# CAN1 register map
Registers from a debugger description file.
Registers are 32-bit, access not given, no defined reset value unless marked. A register's access mark holds for its fields unless they carry their own. Addresses are absolute; registers are grouped by the start of their names; lines under a group give offsets from that group; [hi:lo] are bit positions; {n}, {i} and the like mark numbered series; 'fields as' and 'values as' point back to an identical list; <NAME> marks a mode.

## CAN1
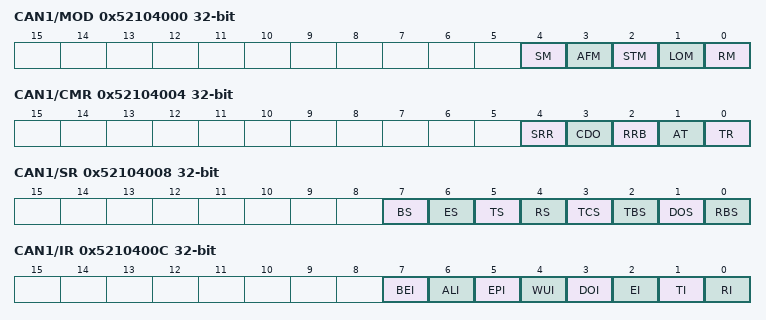
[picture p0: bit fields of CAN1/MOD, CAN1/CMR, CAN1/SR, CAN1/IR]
0x52104000 CAN1/MOD
  [4] SM, [3] AFM, [2] STM, [1] LOM, [0] RM
0x52104004 CAN1/CMR wo
  [4] SRR, [3] CDO, [2] RRB, [1] AT, [0] TR
0x52104008 CAN1/SR ro
  [7] BS, [6] ES, [5] TS, [4] RS, [3] TCS, [2] TBS, [1] DOS, [0] RBS
0x5210400C CAN1/IR ro
  [7] BEI, [6] ALI, [5] EPI, [4] WUI, [3] DOI, [2] EI, [1] TI, [0] RI
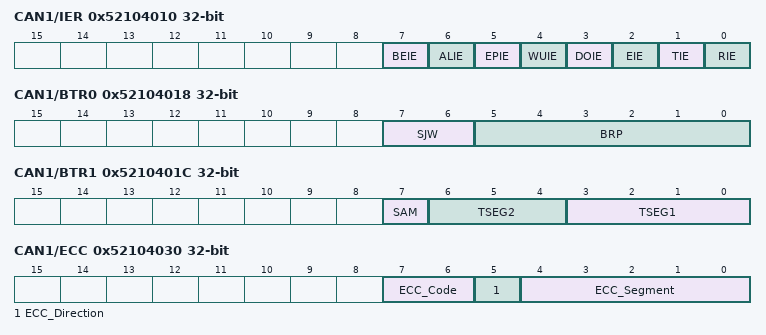
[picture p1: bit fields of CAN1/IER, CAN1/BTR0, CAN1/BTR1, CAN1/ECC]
0x52104010 CAN1/IER
  [7] BEIE, [6] ALIE, [5] EPIE, [4] WUIE, [3] DOIE, [2] EIE, [1] TIE, [0] RIE
0x52104018 CAN1/BTR0
  [7:6] SJW, [5:0] BRP
0x5210401C CAN1/BTR1
  [7] SAM, [6:4] TSEG2, [3:0] TSEG1
0x52104020 CAN1/OCR
  [1:0] OCMODE
0x5210402C CAN1/ALC ro
  [4:0] ALC
0x52104030 CAN1/ECC ro
  [7:6] ECC_Code, [5] ECC_Direction, [4:0] ECC_Segment
0x52104034 CAN1/EWLR
  [7:0] EWLR
0x52104038 CAN1/RXERR
  [7:0] RXERR
0x5210403C CAN1/TXERR
  [7:0] TXERR
{0x52104040+4i} CAN1/WrTransmitBuffer_{i} wo (i=0..12)
  [7:0] WrTransmitBuffer
{0x52104040+4i} CAN1/RdReceiveBuffer_{i} ro (i=0..12)
  [7:0] RdReceiveBuffer
{0x52104040+4i} CAN1/ACR{i} (i=0..3)
  [7:0] ACR
{0x52104050+4i} CAN1/AMR{i} (i=0..3)
  [7:0] AMR
0x52104074 CAN1/RMC ro
  [4:0] RMC
0x52104078 CAN1/RBSA
  [5:0] RBSA
{0x52104080+4i} CAN1/ReceiveFifo_{i} (i=0..63)
  [7:0] ReceiveFifo
{0x52104180+4i} CAN1/RdTransmitBuffer_{i} ro (i=0..12)
  [7:0] RdTransmitBuffer
{0x52104440+4i} CAN1/SyncTransmitBuffer_{i} (i=0..12)
  [7:0] SyncTransmitBuffer
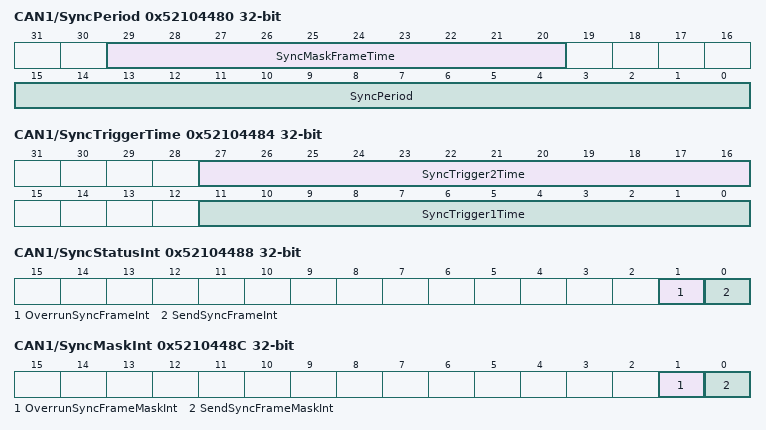
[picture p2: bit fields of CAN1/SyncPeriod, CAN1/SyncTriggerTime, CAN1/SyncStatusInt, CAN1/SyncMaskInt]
0x52104480 CAN1/SyncPeriod
  [29:20] SyncMaskFrameTime, [15:0] SyncPeriod
0x52104484 CAN1/SyncTriggerTime
  [27:16] SyncTrigger2Time, [11:0] SyncTrigger1Time
0x52104488 CAN1/SyncStatusInt ro
  [1] OverrunSyncFrameInt, [0] SendSyncFrameInt
0x5210448C CAN1/SyncMaskInt
  [1] OverrunSyncFrameMaskInt, [0] SendSyncFrameMaskInt
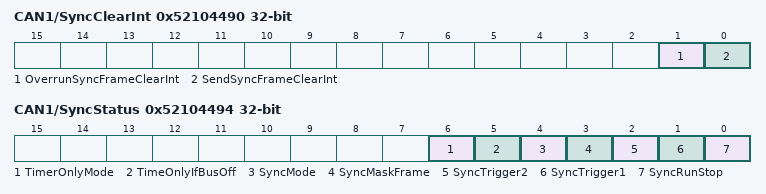
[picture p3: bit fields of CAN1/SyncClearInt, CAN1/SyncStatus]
0x52104490 CAN1/SyncClearInt
  [1] OverrunSyncFrameClearInt, [0] SendSyncFrameClearInt
0x52104494 CAN1/SyncStatus
  [6] TimerOnlyMode, [5] TimeOnlyIfBusOff, [4] SyncMode, [3] SyncMaskFrame ro, [2] SyncTrigger2 ro, [1] SyncTrigger1 ro, [0] SyncRunStop ro
0x52104498 CAN1/SyncClearSetRunStop wo
  [31:0] SyncClearSetRunStop
0x5210449C CAN1/SyncClearSetTrigger wo
  [31:0] SyncClearSetTrigger
0x521044A0 CAN1/SyncPassiveError
  [15:0] SyncPassiveError
